AUTOSAR XML (schema 4-2-2)
package /Components
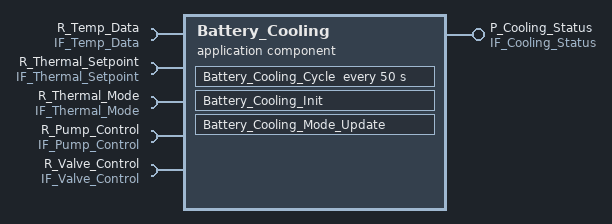
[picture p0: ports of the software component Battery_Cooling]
  application sw component type Battery_Cooling
    provide port P_Cooling_Status: provided-interface=IF_Cooling_Status
    5 x require port:
      R_Temp_Data: required-interface=IF_Temp_Data
      R_Thermal_Setpoint: required-interface=IF_Thermal_Setpoint
      R_Thermal_Mode: required-interface=IF_Thermal_Mode
      R_Pump_Control: required-interface=IF_Pump_Control
      R_Valve_Control: required-interface=IF_Valve_Control
    behavior Battery_Cooling_InternalBehavior
      data received event Battery_Cooling_Setpoint_Update: start-on-event=Battery_Cooling_Cycle
      init event Battery_Cooling_Init_Event: start-on-event=Battery_Cooling_Init
      swc mode switch event Battery_Cooling_Mode_Switch: start-on-event=Battery_Cooling_Mode_Update, activation=ON-TRANSITION, mode=ThermalModeGroup.R_Thermal_Mode.BatteryPriority
      timing event Battery_Cooling_Periodic_50ms: start-on-event=Battery_Cooling_Cycle, period=50
      runnable Battery_Cooling_Init: mode-access-point=R_Thermal_Mode.ThermalModeGroup
        data-read-access:
          access VA_Read_t_batt_coolant_in_Init: accessed-variable=R_Temp_Data.t_batt_coolant_in
        data-receive-point-by-values:
          access VA_Rcv_TargetBatteryFlow_Init: accessed-variable=R_Thermal_Setpoint.target_battery_coolant_flow
          access VA_Rcv_t_battery_pack_Init: accessed-variable=R_Temp_Data.t_battery_pack
        data-send-points:
          access VA_Send_BatteryStatus_Init: accessed-variable=P_Cooling_Status.battery_cooling_status
        data-write-access:
          access VA_Write_BatteryStatus_Init: accessed-variable=P_Cooling_Status.battery_cooling_status
        sync call SCP_GetPumpStatus_Init: operation=R_Pump_Control.op_get_pump_status, timeout=50
      runnable Battery_Cooling_Cycle: minimum-start-interval=50, mode-access-point=R_Thermal_Mode.ThermalModeGroup
        data-read-access:
          4 x access:
            VA_Read_t_battery_pack_Cycle: accessed-variable=R_Temp_Data.t_battery_pack
            VA_Read_t_batt_coolant_in_Cycle: accessed-variable=R_Temp_Data.t_batt_coolant_in
            VA_Read_t_batt_coolant_out_Cycle: accessed-variable=R_Temp_Data.t_batt_coolant_out
            VA_Read_TargetBatteryFlow_Cycle: accessed-variable=R_Thermal_Setpoint.target_battery_coolant_flow
        data-receive-point-by-values:
          access VA_Rcv_TargetBatteryFlow_Cycle: accessed-variable=R_Thermal_Setpoint.target_battery_coolant_flow
        data-send-points:
          access VA_Send_BatteryStatus_Cycle: accessed-variable=P_Cooling_Status.battery_cooling_status
        data-write-access:
          access VA_Write_BatteryStatus_Cycle: accessed-variable=P_Cooling_Status.battery_cooling_status
        sync call SCP_SetPumpSpeed_Cycle: operation=R_Pump_Control.op_set_pump_speed, timeout=50
        sync call SCP_SetValvePosition_Cycle: operation=R_Valve_Control.op_set_valve_position, timeout=50
      runnable Battery_Cooling_Mode_Update: mode-access-point=R_Thermal_Mode.ThermalModeGroup
        data-read-access:
          access VA_Read_t_batt_coolant_out_Mode: accessed-variable=R_Temp_Data.t_batt_coolant_out
        data-receive-point-by-values:
          access VA_Rcv_TargetBatteryFlow_Mode: accessed-variable=R_Thermal_Setpoint.target_battery_coolant_flow
        data-send-points:
          access VA_Send_BatteryStatus_Mode: accessed-variable=P_Cooling_Status.battery_cooling_status
        data-write-access:
          access VA_Write_BatteryStatus_Mode: accessed-variable=P_Cooling_Status.battery_cooling_status
        sync call SCP_GetValveStatus_Mode: operation=R_Valve_Control.op_get_valve_status, timeout=50
